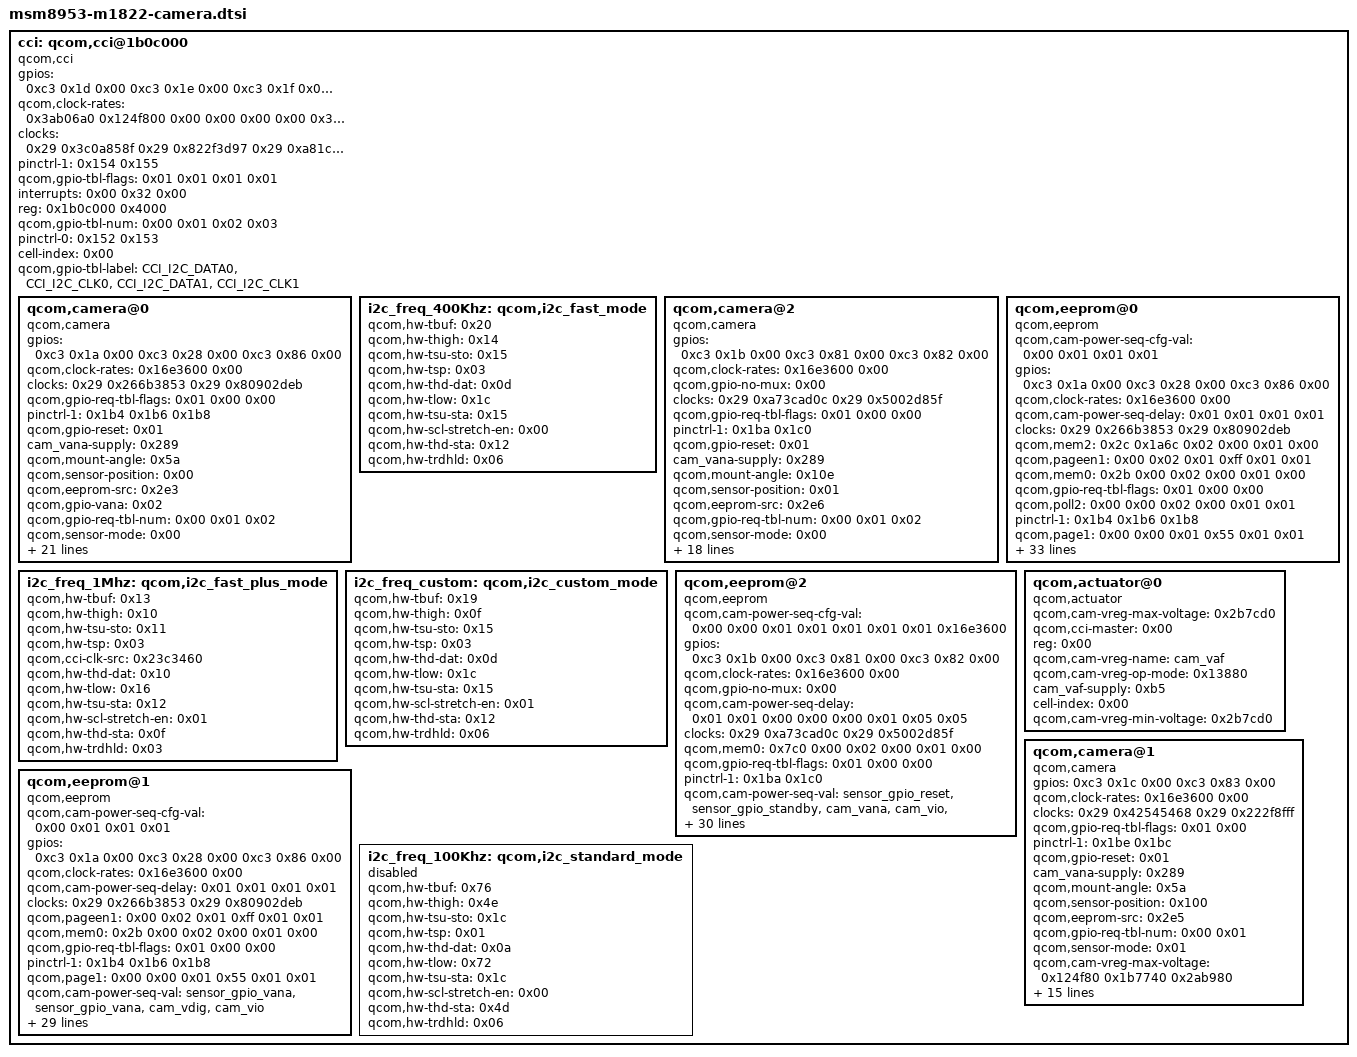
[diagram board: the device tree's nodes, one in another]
		cci: qcom,cci@1b0c000 {
			gpios = <0xc3 0x1d 0x00 0xc3 0x1e 0x00 0xc3 0x1f 0x00 0xc3 0x20 0x00>;
			qcom,clock-rates = <0x3ab06a0 0x124f800 0x00 0x00 0x00 0x00 0x3ab06a0 0x23c3460 0x00 0x00 0x00 0x00>;
			compatible = "qcom,cci";
			clocks = <0x29 0x3c0a858f 0x29 0x822f3d97 0x29 0xa81c11ba 0x29 0xb7dd8824 0x29 0x9894b414 0x29 0x4e814a78>;
			reg-names = "cci";
			pinctrl-1 = <0x154 0x155>;
			clock-names = "ispif_ahb_clk", "cci_src_clk", "cci_ahb_clk", "camss_cci_clk", "camss_ahb_clk", "camss_top_ahb_clk";
			qcom,gpio-tbl-flags = <0x01 0x01 0x01 0x01>;
			status = "ok";
			#address-cells = <0x01>;
			interrupts = <0x00 0x32 0x00>;
			#size-cells = <0x00>;
			phandle = <0x2b7>;
			reg = <0x1b0c000 0x4000>;
			qcom,gpio-tbl-num = <0x00 0x01 0x02 0x03>;
			pinctrl-0 = <0x152 0x153>;
			linux,phandle = <0x2b7>;
			interrupt-names = "cci";
			pinctrl-names = "cci_default", "cci_suspend";
			cell-index = <0x00>;
			qcom,gpio-tbl-label = "CCI_I2C_DATA0", "CCI_I2C_CLK0", "CCI_I2C_DATA1", "CCI_I2C_CLK1";

			qcom,camera@0 {
				gpios = <0xc3 0x1a 0x00 0xc3 0x28 0x00 0xc3 0x86 0x00>;
				qcom,clock-rates = <0x16e3600 0x00>;
				compatible = "qcom,camera";
				clocks = <0x29 0x266b3853 0x29 0x80902deb>;
				qcom,gpio-req-tbl-flags = <0x01 0x00 0x00>;
				pinctrl-1 = <0x1b4 0x1b6 0x1b8>;
				clock-names = "cam_src_clk", "cam_clk";
				qcom,gpio-reset = <0x01>;
				cam_vana-supply = <0x289>;
				qcom,mount-angle = <0x5a>;
				qcom,sensor-position = <0x00>;
				qcom,eeprom-src = <0x2e3>;
				qcom,gpio-vana = <0x02>;
				qcom,gpio-req-tbl-num = <0x00 0x01 0x02>;
				status = "ok";
				qcom,sensor-mode = <0x00>;
				qcom,actuator-src = <0x2e4>;
				qcom,cam-vreg-max-voltage = <0x1b7740 0x100590 0x2b7cd0 0x2ab980>;
				qcom,csid-sd-index = <0x00>;
				qcom,gpio-req-tbl-label = "CAMIF_MCLK0", "CAM_RESET0", "CAM_VANA";
				qcom,cci-master = <0x00>;
				qcom,csiphy-sd-index = <0x00>;
				qcom,led-flash-src = <0x2dd>;
				reg = <0x00>;
				pinctrl-0 = <0x1b3 0x1b5 0x1b7>;
				qcom,cam-vreg-name = "cam_vio", "cam_vdig", "cam_vaf", "cam_vana";
				qcom,cam-vreg-op-mode = <0x13880 0x19a28 0x186a0 0x13880>;
				cam_vdig-supply = <0x282>;
				cam_vaf-supply = <0xb5>;
				pinctrl-names = "cam_default", "cam_suspend";
				cell-index = <0x00>;
				cam_vio-supply = <0x2e2>;
				qcom,cam-vreg-min-voltage = <0x1b7740 0x100590 0x2b7cd0 0x2ab980>;
			};

			i2c_freq_400Khz: qcom,i2c_fast_mode {
				qcom,hw-tbuf = <0x20>;
				qcom,hw-thigh = <0x14>;
				qcom,hw-tsu-sto = <0x15>;
				status = "ok";
				phandle = <0x2b9>;
				qcom,hw-tsp = <0x03>;
				qcom,hw-thd-dat = <0x0d>;
				qcom,hw-tlow = <0x1c>;
				linux,phandle = <0x2b9>;
				qcom,hw-tsu-sta = <0x15>;
				qcom,hw-scl-stretch-en = <0x00>;
				qcom,hw-thd-sta = <0x12>;
				qcom,hw-trdhld = <0x06>;
			};

			qcom,camera@2 {
				gpios = <0xc3 0x1b 0x00 0xc3 0x81 0x00 0xc3 0x82 0x00>;
				qcom,clock-rates = <0x16e3600 0x00>;
				qcom,gpio-no-mux = <0x00>;
				compatible = "qcom,camera";
				clocks = <0x29 0xa73cad0c 0x29 0x5002d85f>;
				qcom,gpio-req-tbl-flags = <0x01 0x00 0x00>;
				pinctrl-1 = <0x1ba 0x1c0>;
				clock-names = "cam_src_clk", "cam_clk";
				qcom,gpio-reset = <0x01>;
				cam_vana-supply = <0x289>;
				qcom,mount-angle = <0x10e>;
				qcom,sensor-position = <0x01>;
				qcom,eeprom-src = <0x2e6>;
				qcom,gpio-req-tbl-num = <0x00 0x01 0x02>;
				status = "ok";
				qcom,sensor-mode = <0x00>;
				qcom,cam-vreg-max-voltage = <0x124f80 0x1b7740 0x2ab980>;
				qcom,csid-sd-index = <0x02>;
				qcom,gpio-req-tbl-label = "CAMIF_MCLK2", "CAM_RESET2", "CAM_STANDBY2";
				qcom,cci-master = <0x01>;
				qcom,csiphy-sd-index = <0x02>;
				reg = <0x02>;
				pinctrl-0 = <0x1b9 0x1bf>;
				qcom,gpio-standby = <0x02>;
				qcom,cam-vreg-name = "cam_vdig", "cam_vio", "cam_vana";
				qcom,cam-vreg-op-mode = <0x19a28 0x13880 0x13880>;
				cam_vdig-supply = <0x28a>;
				pinctrl-names = "cam_default", "cam_suspend";
				cell-index = <0x02>;
				cam_vio-supply = <0x2e2>;
				qcom,cam-vreg-min-voltage = <0x124f80 0x1b7740 0x2ab980>;
			};

			qcom,eeprom@0 {
				qcom,cam-power-seq-cfg-val = <0x00 0x01 0x01 0x01>;
				gpios = <0xc3 0x1a 0x00 0xc3 0x28 0x00 0xc3 0x86 0x00>;
				qcom,clock-rates = <0x16e3600 0x00>;
				compatible = "qcom,eeprom";
				qcom,cam-power-seq-delay = <0x01 0x01 0x01 0x01>;
				clocks = <0x29 0x266b3853 0x29 0x80902deb>;
				qcom,mem2 = <0x2c 0x1a6c 0x02 0x00 0x01 0x00>;
				qcom,pageen1 = <0x00 0x02 0x01 0xff 0x01 0x01>;
				qcom,mem0 = <0x2b 0x00 0x02 0x00 0x01 0x00>;
				qcom,gpio-req-tbl-flags = <0x01 0x00 0x00>;
				qcom,poll2 = <0x00 0x00 0x02 0x00 0x01 0x01>;
				pinctrl-1 = <0x1b4 0x1b6 0x1b8>;
				qcom,page1 = <0x00 0x00 0x01 0x55 0x01 0x01>;
				qcom,cam-power-seq-val = "sensor_gpio_vana", "sensor_gpio_vana", "cam_vdig", "cam_vio";
				qcom,poll0 = <0x00 0x00 0x02 0x00 0x01 0x01>;
				clock-names = "cam_src_clk", "cam_clk";
				qcom,gpio-reset = <0x01>;
				qcom,eeprom-name = "gt24c64a_imx362";
				cam_vana-supply = <0x289>;
				qcom,cam-power-seq-type = "sensor_gpio", "sensor_gpio", "sensor_vreg", "sensor_vreg";
				qcom,gpio-vana = <0x02>;
				qcom,gpio-req-tbl-num = <0x00 0x01 0x02>;
				status = "ok";
				qcom,pageen2 = <0x00 0x02 0x01 0xff 0x01 0x01>;
				qcom,cam-vreg-max-voltage = <0x1b7740 0x100590 0x2ab980>;
				phandle = <0x2e3>;
				qcom,mem1 = <0x132f 0x2b 0x02 0x00 0x01 0x00>;
				qcom,pageen0 = <0x00 0x02 0x01 0xff 0x01 0x01>;
				qcom,page2 = <0x00 0x00 0x01 0x55 0x01 0x01>;
				qcom,gpio-req-tbl-label = "CAMIF_MCLK0", "CAM_RESET0", "CAM_VANA";
				qcom,cci-master = <0x00>;
				reg = <0x00>;
				qcom,num-blocks = <0x03>;
				qcom,poll1 = <0x00 0x00 0x02 0x00 0x01 0x01>;
				pinctrl-0 = <0x1b3 0x1b5 0x1b7>;
				qcom,page0 = <0x00 0x00 0x01 0x55 0x01 0x01>;
				qcom,cam-vreg-name = "cam_vio", "cam_vdig", "cam_vana";
				qcom,cam-vreg-op-mode = <0x13880 0x19a28 0x13880>;
				linux,phandle = <0x2e3>;
				cam_vdig-supply = <0x282>;
				qcom,slave-addr = <0xa0>;
				pinctrl-names = "cam_default", "cam_suspend";
				cell-index = <0x00>;
				cam_vio-supply = <0x2e2>;
				qcom,cam-vreg-min-voltage = <0x1b7740 0x100590 0x2ab980>;
			};

			i2c_freq_1Mhz: qcom,i2c_fast_plus_mode {
				qcom,hw-tbuf = <0x13>;
				qcom,hw-thigh = <0x10>;
				qcom,hw-tsu-sto = <0x11>;
				status = "ok";
				phandle = <0x2bb>;
				qcom,hw-tsp = <0x03>;
				qcom,cci-clk-src = <0x23c3460>;
				qcom,hw-thd-dat = <0x10>;
				qcom,hw-tlow = <0x16>;
				linux,phandle = <0x2bb>;
				qcom,hw-tsu-sta = <0x12>;
				qcom,hw-scl-stretch-en = <0x01>;
				qcom,hw-thd-sta = <0x0f>;
				qcom,hw-trdhld = <0x03>;
			};

			i2c_freq_custom: qcom,i2c_custom_mode {
				qcom,hw-tbuf = <0x19>;
				qcom,hw-thigh = <0x0f>;
				qcom,hw-tsu-sto = <0x15>;
				status = "ok";
				phandle = <0x2ba>;
				qcom,hw-tsp = <0x03>;
				qcom,hw-thd-dat = <0x0d>;
				qcom,hw-tlow = <0x1c>;
				linux,phandle = <0x2ba>;
				qcom,hw-tsu-sta = <0x15>;
				qcom,hw-scl-stretch-en = <0x01>;
				qcom,hw-thd-sta = <0x12>;
				qcom,hw-trdhld = <0x06>;
			};

			qcom,eeprom@2 {
				qcom,cam-power-seq-cfg-val = <0x00 0x00 0x01 0x01 0x01 0x01 0x01 0x16e3600>;
				gpios = <0xc3 0x1b 0x00 0xc3 0x81 0x00 0xc3 0x82 0x00>;
				qcom,clock-rates = <0x16e3600 0x00>;
				qcom,gpio-no-mux = <0x00>;
				compatible = "qcom,eeprom";
				qcom,cam-power-seq-delay = <0x01 0x01 0x00 0x00 0x00 0x01 0x05 0x05>;
				clocks = <0x29 0xa73cad0c 0x29 0x5002d85f>;
				qcom,mem0 = <0x7c0 0x00 0x02 0x00 0x01 0x00>;
				qcom,gpio-req-tbl-flags = <0x01 0x00 0x00>;
				pinctrl-1 = <0x1ba 0x1c0>;
				qcom,cam-power-seq-val = "sensor_gpio_reset", "sensor_gpio_standby", "cam_vana", "cam_vio", "cam_vdig", "sensor_gpio_reset", "sensor_gpio_standby", "sensor_cam_mclk";
				qcom,poll0 = <0x00 0x00 0x02 0x00 0x01 0x00>;
				clock-names = "cam_src_clk", "cam_clk";
				qcom,gpio-reset = <0x01>;
				qcom,eeprom-name = "s5k4h7";
				cam_vana-supply = <0x289>;
				qcom,cam-power-seq-type = "sensor_gpio", "sensor_gpio", "sensor_vreg", "sensor_vreg", "sensor_vreg", "sensor_gpio", "sensor_gpio", "sensor_clk";
				qcom,gpio-req-tbl-num = <0x00 0x01 0x02>;
				status = "ok";
				qcom,cam-vreg-max-voltage = <0x124f80 0x1b7740 0x2ab980>;
				phandle = <0x2e6>;
				qcom,gpio-req-tbl-label = "CAMIF_MCLK2", "CAM_RESET2", "CAM_STANDBY2";
				qcom,cci-master = <0x01>;
				reg = <0x02>;
				qcom,num-blocks = <0x01>;
				pinctrl-0 = <0x1b9 0x1bf>;
				qcom,page0 = <0x00 0x100 0x02 0x01 0x01 0x01>;
				qcom,gpio-standby = <0x02>;
				qcom,cam-vreg-name = "cam_vdig", "cam_vio", "cam_vana";
				qcom,cam-vreg-op-mode = <0x19a28 0x13880 0x13880>;
				linux,phandle = <0x2e6>;
				cam_vdig-supply = <0x28a>;
				qcom,slave-addr = <0x5a>;
				pinctrl-names = "cam_default", "cam_suspend";
				cell-index = <0x02>;
				cam_vio-supply = <0x2e2>;
				qcom,cam-vreg-min-voltage = <0x124f80 0x1b7740 0x2ab980>;
			};

			qcom,actuator@0 {
				compatible = "qcom,actuator";
				qcom,cam-vreg-max-voltage = <0x2b7cd0>;
				phandle = <0x2e4>;
				qcom,cci-master = <0x00>;
				reg = <0x00>;
				qcom,cam-vreg-name = "cam_vaf";
				qcom,cam-vreg-op-mode = <0x13880>;
				linux,phandle = <0x2e4>;
				cam_vaf-supply = <0xb5>;
				cell-index = <0x00>;
				qcom,cam-vreg-min-voltage = <0x2b7cd0>;
			};

			qcom,camera@1 {
				gpios = <0xc3 0x1c 0x00 0xc3 0x83 0x00>;
				qcom,clock-rates = <0x16e3600 0x00>;
				compatible = "qcom,camera";
				clocks = <0x29 0x42545468 0x29 0x222f8fff>;
				qcom,gpio-req-tbl-flags = <0x01 0x00>;
				pinctrl-1 = <0x1be 0x1bc>;
				clock-names = "cam_src_clk", "cam_clk";
				qcom,gpio-reset = <0x01>;
				cam_vana-supply = <0x289>;
				qcom,mount-angle = <0x5a>;
				qcom,sensor-position = <0x100>;
				qcom,eeprom-src = <0x2e5>;
				qcom,gpio-req-tbl-num = <0x00 0x01>;
				status = "ok";
				qcom,sensor-mode = <0x01>;
				qcom,cam-vreg-max-voltage = <0x124f80 0x1b7740 0x2ab980>;
				qcom,csid-sd-index = <0x01>;
				qcom,gpio-req-tbl-label = "CAMIF_MCLK1", "CAM_RESET1";
				qcom,cci-master = <0x01>;
				qcom,csiphy-sd-index = <0x01>;
				reg = <0x01>;
				pinctrl-0 = <0x1bd 0x1bb>;
				qcom,cam-vreg-name = "cam_vdig", "cam_vio", "cam_vana";
				qcom,cam-vreg-op-mode = <0x30d40 0x13880 0x13880>;
				cam_vdig-supply = <0x28a>;
				pinctrl-names = "cam_default", "cam_suspend";
				cell-index = <0x01>;
				cam_vio-supply = <0x2e2>;
				qcom,cam-vreg-min-voltage = <0x124f80 0x1b7740 0x2ab980>;
			};

			qcom,eeprom@1 {
				qcom,cam-power-seq-cfg-val = <0x00 0x01 0x01 0x01>;
				gpios = <0xc3 0x1a 0x00 0xc3 0x28 0x00 0xc3 0x86 0x00>;
				qcom,clock-rates = <0x16e3600 0x00>;
				compatible = "qcom,eeprom";
				qcom,cam-power-seq-delay = <0x01 0x01 0x01 0x01>;
				clocks = <0x29 0x266b3853 0x29 0x80902deb>;
				qcom,pageen1 = <0x00 0x02 0x01 0xff 0x01 0x01>;
				qcom,mem0 = <0x2b 0x00 0x02 0x00 0x01 0x00>;
				qcom,gpio-req-tbl-flags = <0x01 0x00 0x00>;
				pinctrl-1 = <0x1b4 0x1b6 0x1b8>;
				qcom,page1 = <0x00 0x00 0x01 0x55 0x01 0x01>;
				qcom,cam-power-seq-val = "sensor_gpio_vana", "sensor_gpio_vana", "cam_vdig", "cam_vio";
				qcom,poll0 = <0x00 0x00 0x02 0x00 0x01 0x01>;
				clock-names = "cam_src_clk", "cam_clk";
				qcom,gpio-reset = <0x01>;
				qcom,eeprom-name = "s5k5e9";
				cam_vana-supply = <0x289>;
				qcom,cam-power-seq-type = "sensor_gpio", "sensor_gpio", "sensor_vreg", "sensor_vreg";
				qcom,gpio-vana = <0x02>;
				qcom,gpio-req-tbl-num = <0x00 0x01 0x02>;
				status = "ok";
				qcom,cam-vreg-max-voltage = <0x1b7740 0x100590 0x2ab980>;
				phandle = <0x2e5>;
				qcom,mem1 = <0x712 0x135a 0x02 0x00 0x01 0x00>;
				qcom,pageen0 = <0x00 0x02 0x01 0xff 0x01 0x01>;
				qcom,gpio-req-tbl-label = "CAMIF_MCLK0", "CAM_RESET0", "CAM_VANA";
				qcom,cci-master = <0x00>;
				reg = <0x01>;
				qcom,num-blocks = <0x02>;
				qcom,poll1 = <0x00 0x00 0x02 0x00 0x01 0x01>;
				pinctrl-0 = <0x1b3 0x1b5 0x1b7>;
				qcom,page0 = <0x00 0x00 0x01 0x55 0x01 0x01>;
				qcom,cam-vreg-name = "cam_vio", "cam_vdig", "cam_vana";
				qcom,cam-vreg-op-mode = <0x13880 0x19a28 0x13880>;
				linux,phandle = <0x2e5>;
				cam_vdig-supply = <0x282>;
				qcom,slave-addr = <0xa0>;
				pinctrl-names = "cam_default", "cam_suspend";
				cell-index = <0x01>;
				cam_vio-supply = <0x2e2>;
				qcom,cam-vreg-min-voltage = <0x1b7740 0x100590 0x2ab980>;
			};

			i2c_freq_100Khz: qcom,i2c_standard_mode {
				qcom,hw-tbuf = <0x76>;
				qcom,hw-thigh = <0x4e>;
				qcom,hw-tsu-sto = <0x1c>;
				status = "disabled";
				phandle = <0x2b8>;
				qcom,hw-tsp = <0x01>;
				qcom,hw-thd-dat = <0x0a>;
				qcom,hw-tlow = <0x72>;
				linux,phandle = <0x2b8>;
				qcom,hw-tsu-sta = <0x1c>;
				qcom,hw-scl-stretch-en = <0x00>;
				qcom,hw-thd-sta = <0x4d>;
				qcom,hw-trdhld = <0x06>;
			};
		};
